# STM32F411CCU6 register map
File version: 1.0
Registers are 32-bit, access not given, reset 0x0 unless marked. A register's access mark holds for its fields unless they carry their own. Offsets are from the block's base; [hi:lo] are bit positions; {n}, {i} and the like mark numbered series.

## ADC1
Base 0x40012000
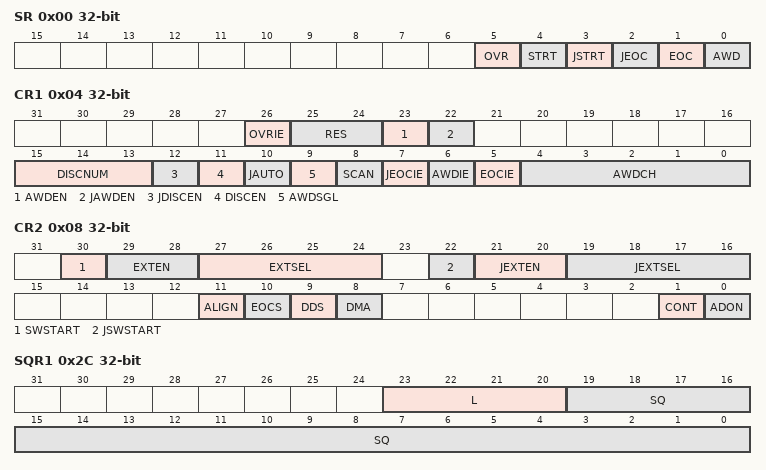
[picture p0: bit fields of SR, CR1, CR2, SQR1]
0x00 SR
  [5] OVR, [4] STRT, [3] JSTRT, [2] JEOC, [1] EOC, [0] AWD
0x04 CR1
  [26] OVRIE, [25:24] RES, [23] AWDEN, [22] JAWDEN, [15:13] DISCNUM, [12] JDISCEN, [11] DISCEN, [10] JAUTO, [9] AWDSGL, [8] SCAN, [7] JEOCIE, [6] AWDIE, [5] EOCIE, [4:0] AWDCH
0x08 CR2
  [30] SWSTART, [29:28] EXTEN, [27:24] EXTSEL, [22] JSWSTART, [21:20] JEXTEN, [19:16] JEXTSEL, [11] ALIGN, [10] EOCS, [9] DDS, [8] DMA, [1] CONT, [0] ADON
0x0C SMPR1
  [31:0] SMP
0x10 SMPR2
  [31:0] SMP
{0x10+4i} JOFR{i} (i=1..4)
  [11:0] JOFFSET{i}
0x24 HTR
  [11:0] HT
0x28 LTR
  [11:0] LT
0x2C SQR1
  [23:20] L, [19:0] SQ
0x30 SQR2
  [29:0] SQ
0x34 SQR3
  [29:0] SQ
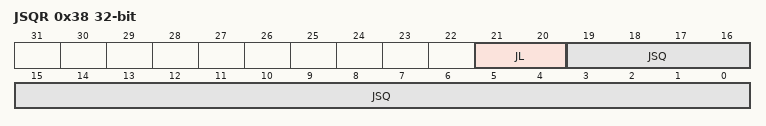
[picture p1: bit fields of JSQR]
0x38 JSQR
  [21:20] JL, [19:0] JSQ
{0x38+4i} JDR{i} (i=1..4)
  [15:0] JDATA
0x4C DR
  [15:0] DATA

## SDIO
Base 0x40012C00
0x00 POWER
  [1:0] PWRCTRL
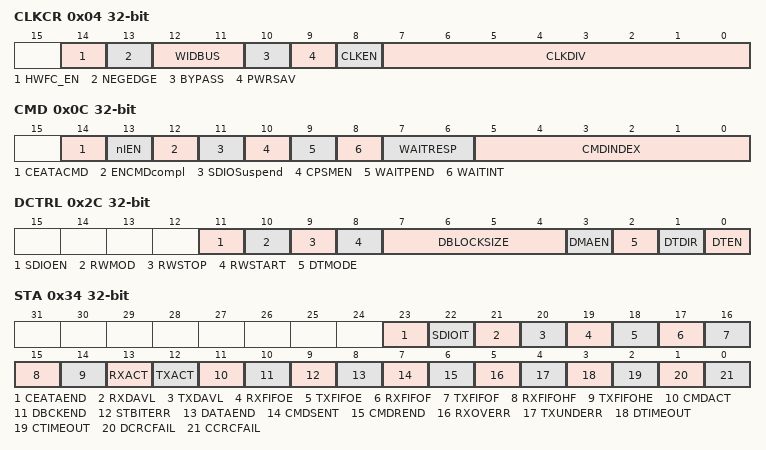
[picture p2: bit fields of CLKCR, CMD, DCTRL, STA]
0x04 CLKCR
  [14] HWFC_EN, [13] NEGEDGE, [12:11] WIDBUS, [10] BYPASS, [9] PWRSAV, [8] CLKEN, [7:0] CLKDIV
0x08 ARG
  [31:0] CMDARG
0x0C CMD
  [14] CEATACMD, [13] nIEN, [12] ENCMDcompl, [11] SDIOSuspend, [10] CPSMEN, [9] WAITPEND, [8] WAITINT, [7:6] WAITRESP, [5:0] CMDINDEX
0x10 RESPCMD
  [5:0] RESPCMD
{0x10+4i} RESP{i} (i=1..4)
  [31:0] CARDSTATUS{i}
0x24 DTIMER
  [31:0] DATATIME
0x28 DLEN
  [24:0] DATALENGTH
0x2C DCTRL
  [11] SDIOEN, [10] RWMOD, [9] RWSTOP, [8] RWSTART, [7:4] DBLOCKSIZE, [3] DMAEN, [2] DTMODE, [1] DTDIR, [0] DTEN
0x30 DCOUNT
  [24:0] DATACOUNT
0x34 STA
  [23] CEATAEND, [22] SDIOIT, [21] RXDAVL, [20] TXDAVL, [19] RXFIFOE, [18] TXFIFOE, [17] RXFIFOF, [16] TXFIFOF, [15] RXFIFOHF, [14] TXFIFOHE, [13] RXACT, [12] TXACT, [11] CMDACT, [10] DBCKEND, [9] STBITERR, [8] DATAEND, [7] CMDSENT, [6] CMDREND, [5] RXOVERR, [4] TXUNDERR, [3] DTIMEOUT, [2] CTIMEOUT, [1] DCRCFAIL, [0] CCRCFAIL
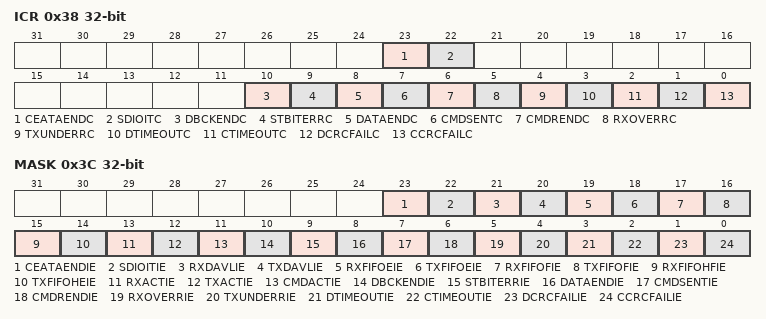
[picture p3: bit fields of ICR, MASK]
0x38 ICR
  [23] CEATAENDC, [22] SDIOITC, [10] DBCKENDC, [9] STBITERRC, [8] DATAENDC, [7] CMDSENTC, [6] CMDRENDC, [5] RXOVERRC, [4] TXUNDERRC, [3] DTIMEOUTC, [2] CTIMEOUTC, [1] DCRCFAILC, [0] CCRCFAILC
0x3C MASK
  [23] CEATAENDIE, [22] SDIOITIE, [21] RXDAVLIE, [20] TXDAVLIE, [19] RXFIFOEIE, [18] TXFIFOEIE, [17] RXFIFOFIE, [16] TXFIFOFIE, [15] RXFIFOHFIE, [14] TXFIFOHEIE, [13] RXACTIE, [12] TXACTIE, [11] CMDACTIE, [10] DBCKENDIE, [9] STBITERRIE, [8] DATAENDIE, [7] CMDSENTIE, [6] CMDRENDIE, [5] RXOVERRIE, [4] TXUNDERRIE, [3] DTIMEOUTIE, [2] CTIMEOUTIE, [1] DCRCFAILIE, [0] CCRCFAILIE
0x48 FIFOCNT
  [23:0] FIFOCOUNT
0x80 FIFO
  [31:0] FIF0Data

## SYSCFG
Base 0x40013800
0x00 MEMRMP
  [1:0] MEM_MODE
0x04 PMC
  [16] ADC1DC2
{0x4+4i} EXTICR{i} (i=1..4)
0x20 CMPCR

## EXTI
Base 0x40013C00
0x00 IMR
0x04 EMR
0x08 RTSR
0x0C FTSR
0x10 SWIER
0x14 PR

## TIM9
Base 0x40014000
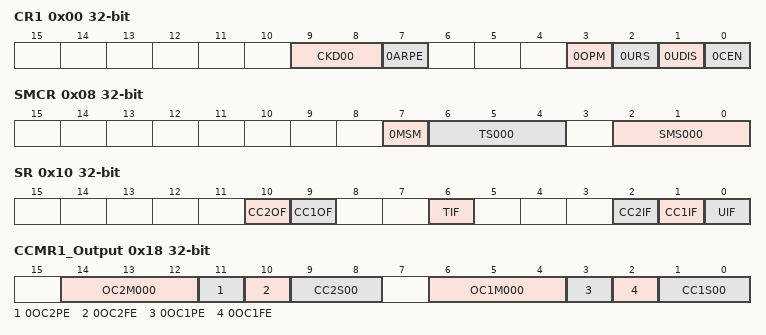
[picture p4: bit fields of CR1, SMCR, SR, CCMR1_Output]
0x00 CR1
  [9:8] CKD00, [7] 0ARPE, [3] 0OPM, [2] 0URS, [1] 0UDIS, [0] 0CEN
0x08 SMCR
  [7] 0MSM, [6:4] TS000, [2:0] SMS000
0x0C DIER
0x10 SR
  [10] CC2OF, [9] CC1OF, [6] TIF, [2] CC2IF, [1] CC1IF, [0] UIF
0x14 EGR
0x18 CCMR1_Output
  [14:12] OC2M000, [11] 0OC2PE, [10] 0OC2FE, [9:8] CC2S00, [6:4] OC1M000, [3] 0OC1PE, [2] 0OC1FE, [1:0] CC1S00
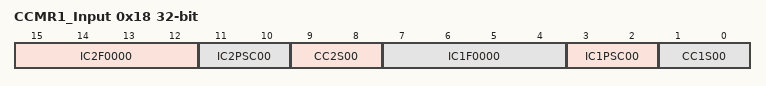
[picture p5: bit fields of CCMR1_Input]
0x18 CCMR1_Input
  [15:12] IC2F0000, [11:10] IC2PSC00, [9:8] CC2S00, [7:4] IC1F0000, [3:2] IC1PSC00, [1:0] CC1S00
0x20 CCER
0x24 CNT
0x28 PSC
0x2C ARR
0x34 CCR1
0x38 CCR2

## TIM10
Base 0x40014400
Same registers: TIM11 0x40014800
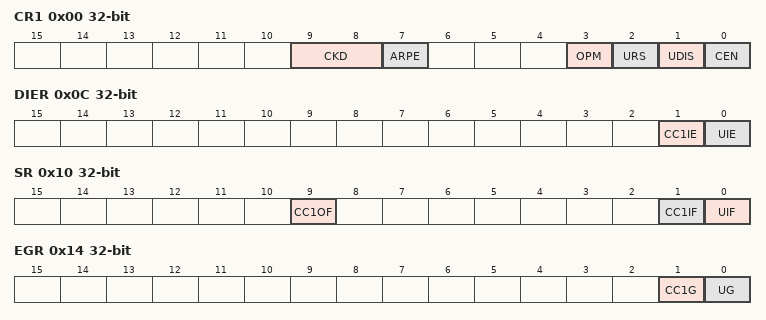
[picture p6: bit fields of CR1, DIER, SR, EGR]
0x00 CR1
  [9:8] CKD, [7] ARPE, [3] OPM, [2] URS, [1] UDIS, [0] CEN
0x08 SMCR
0x0C DIER
  [1] CC1IE, [0] UIE
0x10 SR
  [9] CC1OF, [1] CC1IF, [0] UIF
0x14 EGR
  [1] CC1G, [0] UG
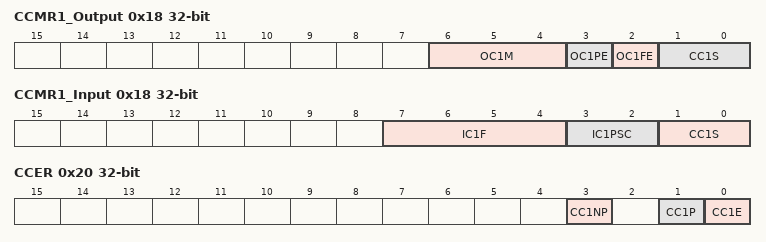
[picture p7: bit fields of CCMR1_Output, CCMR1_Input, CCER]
0x18 CCMR1_Output
  [6:4] OC1M, [3] OC1PE, [2] OC1FE, [1:0] CC1S
0x18 CCMR1_Input
  [7:4] IC1F, [3:2] IC1PSC, [1:0] CC1S
0x20 CCER
  [3] CC1NP, [1] CC1P, [0] CC1E
0x24 CNT
  [15:0] CNT
0x28 PSC
  [15:0] PSC
0x34 CCR1
  [15:0] CCR1
0x50 OR
  [1:0] TI1_RMP

## GPIOA
Base 0x40020000
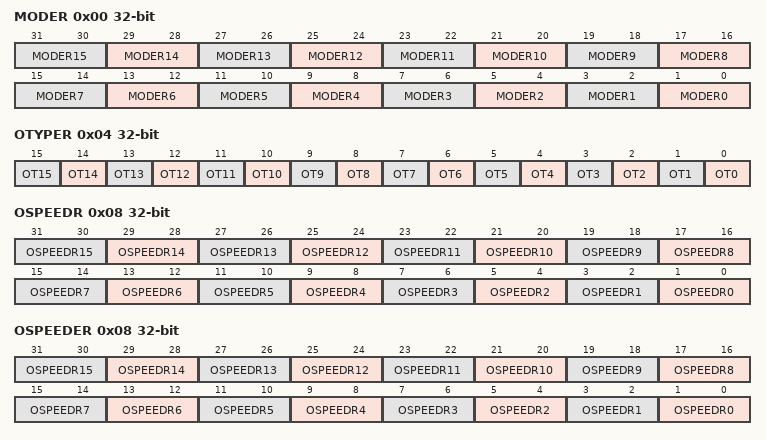
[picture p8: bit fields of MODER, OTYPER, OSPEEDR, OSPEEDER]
0x00 MODER
  [2n+1:2n] MODER{n} (n=0..15)
0x04 OTYPER
  [n] OT{n} (n=0..15)
0x08 OSPEEDR
  [2n+1:2n] OSPEEDR{n} (n=0..15)
0x08 OSPEEDER
  [2n+1:2n] OSPEEDR{n} (n=0..15)
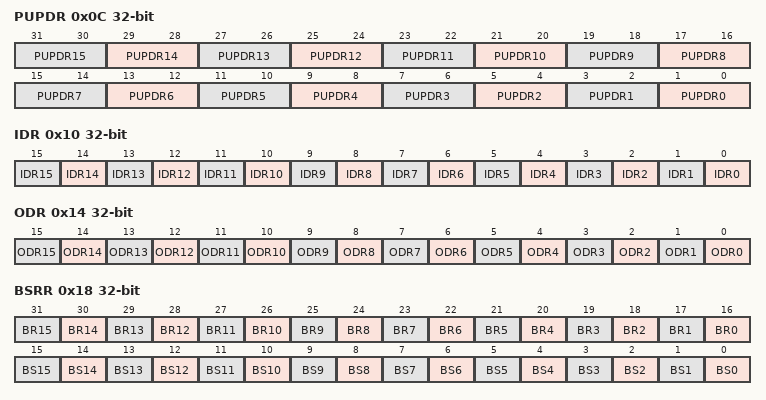
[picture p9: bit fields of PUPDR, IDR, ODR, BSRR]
0x0C PUPDR
  [2n+1:2n] PUPDR{n} (n=0..15)
0x10 IDR
  [n] IDR{n} (n=0..15)
0x14 ODR
  [n] ODR{n} (n=0..15)
0x18 BSRR
  [n+16] BR{n} (n=0..15), [n] BS{n} (n=0..15)
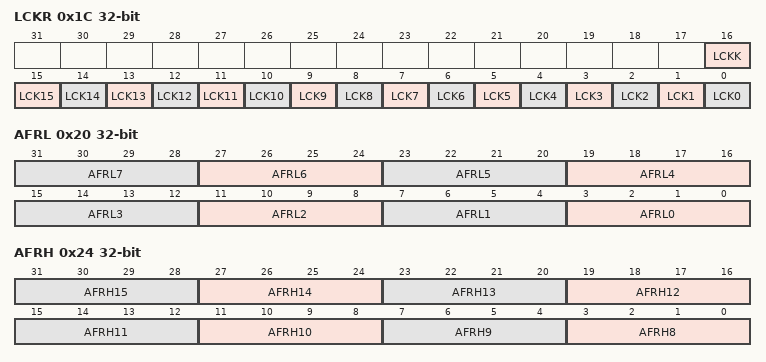
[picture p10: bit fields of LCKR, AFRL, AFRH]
0x1C LCKR
  [16] LCKK, [n] LCK{n} (n=0..15)
0x20 AFRL
  [4n+3:4n] AFRL{n} (n=0..7)
0x24 AFRH
  [4n-29:4n-32] AFRH{n} (n=8..15)

## GPIOB
Base 0x40020400
Registers as GPIOA, without OSPEEDER.

## GPIOC
Base 0x40020800
Registers as GPIOA, without OSPEEDER.

## GPIOD
Base 0x40020C00
Registers as GPIOA, without OSPEEDER.

## GPIOE
Base 0x40021000
Registers as GPIOA, without OSPEEDER.

## GPIOH
Base 0x40021C00
Registers as GPIOA, without OSPEEDER.
